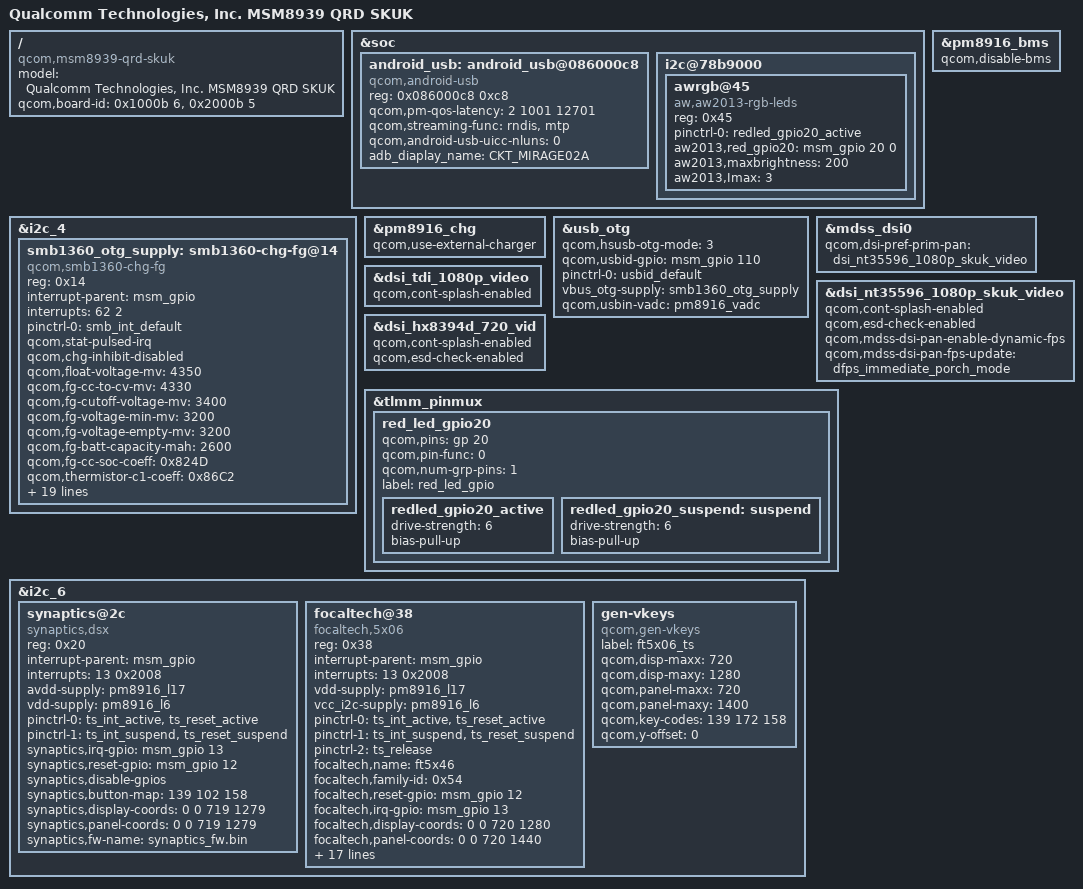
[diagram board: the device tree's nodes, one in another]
/* Copyright (c) 2014, The Linux Foundation. All rights reserved.
 *
 * This program is free software; you can redistribute it and/or modify
 * it under the terms of the GNU General Public License version 2 and
 * only version 2 as published by the Free Software Foundation.
 *
 * This program is distributed in the hope that it will be useful,
 * but WITHOUT ANY WARRANTY; without even the implied warranty of
 * MERCHANTABILITY or FITNESS FOR A PARTICULAR PURPOSE.  See the
 * GNU General Public License for more details.
 */

/dts-v1/;

#include "msm8939.dtsi"
#include "msm8939-qrd-skuk.dtsi"
#include "dsi-panel-nt35596-1080p-skuk-video.dtsi"
#include "dsi-panel-tdi-1080p-video.dtsi"
#include "dsi-panel-hx8394d-720p-video.dtsi"
#include "msm8939-camera-sensor-qrd.dtsi"

/ {
	model = "Qualcomm Technologies, Inc. MSM8939 QRD SKUK";
	compatible = "qcom,msm8939-qrd-skuk", "qcom,msm8939-qrd", "qcom,msm8939", "qcom,qrd";
	qcom,board-id = <0x1000b 6>, <0x2000b 5>;
};

&soc {
	android_usb: android_usb@086000c8 {
		compatible = "qcom,android-usb";
		reg = <0x086000c8 0xc8>;
		qcom,pm-qos-latency = <2 1001 12701>;
		qcom,streaming-func = "rndis","mtp";
		qcom,android-usb-uicc-nluns = /bits/ 8 <0>;
		adb_diaplay_name = "CKT_MIRAGE02A";
	};
};

&i2c_4 {
	smb1360_otg_supply: smb1360-chg-fg@14 {
		compatible = "qcom,smb1360-chg-fg";
		reg = <0x14>;
		interrupt-parent = <&msm_gpio>;
		interrupts = <62 2>;
		pinctrl-names = "default";
		pinctrl-0 = <&smb_int_default>;
		qcom,stat-pulsed-irq;
		qcom,chg-inhibit-disabled;
		/*battery capacity*/
		qcom,float-voltage-mv = <4350>;
		qcom,fg-cc-to-cv-mv = <4330>;
		qcom,fg-cutoff-voltage-mv = <3400>;
		qcom,fg-voltage-min-mv = <3200>;
		qcom,fg-voltage-empty-mv = <3200>;
		qcom,fg-batt-capacity-mah = <2600>;
		qcom,fg-cc-soc-coeff = <0x824D>;
		qcom,thermistor-c1-coeff = <0x86C2>;
		qcom,iterm-ma = <200>;
		qcom,charging-timeout = <1536>;
		qcom,otg-batt-curr-limit = <1500>;
		qcom,recharge-thresh-mv = <100>;
		qcom,thermal-mitigation = <1000 600 300 0>;
	//	qcom,fg-auto-recharge-soc = <99>;
		qcom,empty-soc-disabled;
		regulator-name = "smb1360_otg_vreg";
		/*battery-profile selection properties*/
		qcom,batt-profile-select;
		qcom,smb1360-vadc = <&pm8916_vadc>;
		qcom,batt-id-vref-uv = <1800000>;
		qcom,batt-id-rpullup-kohm = <100>;
		qcom,profile-a-rid-kohm = <33>;
		qcom,profile-b-rid-kohm = <91>;
		qcom,shdn-after-pwroff;
		qcom,config-hard-thresholds;
		qcom,hot-bat-decidegc = <550>;
		qcom,cold-bat-decidegc = <(-150)>;
		qcom,fg-reset-at-pon;
		qcom,hot-bat-mv = <4100>;
	};
};

&pm8916_chg {
	status = "ok";
	qcom,use-external-charger;
};

&pm8916_bms {
	status = "ok";
	qcom,disable-bms;
};
&usb_otg {
	qcom,hsusb-otg-mode = <3>;
	qcom,usbid-gpio = <&msm_gpio 110 0>;
	pinctrl-names = "default";
	pinctrl-0 = <&usbid_default>;
	vbus_otg-supply = <&smb1360_otg_supply>;
	qcom,usbin-vadc = <&pm8916_vadc>;
};
&mdss_dsi0 {
	qcom,dsi-pref-prim-pan = <&dsi_nt35596_1080p_skuk_video>;
};

&dsi_nt35596_1080p_skuk_video {
	qcom,cont-splash-enabled;
	qcom,esd-check-enabled;
	qcom,mdss-dsi-pan-enable-dynamic-fps;
	qcom,mdss-dsi-pan-fps-update = "dfps_immediate_porch_mode";
};


&dsi_tdi_1080p_video {
	qcom,cont-splash-enabled;
};

&dsi_hx8394d_720_vid {
	qcom,cont-splash-enabled;
	qcom,esd-check-enabled;
};

&tlmm_pinmux{
		red_led_gpio20{
			qcom,pins = <&gp 20>;
			qcom,pin-func = <0>;
			qcom,num-grp-pins = <1>;
			label = "red_led_gpio";

			redled_gpio20_active: redled_gpio20_active {
				drive-strength = <6>;
				bias-pull-up;
			};

			redled_gpio20_suspend: suspend {
				drive-strength = <6>;
				bias-pull-up;
			};
		};
};
&soc {
	i2c@78b9000 { /* BLSP1 QUP5 */
		awrgb@45 {
			compatible = "aw,aw2013-rgb-leds";
			reg = <0x45>;
			pinctrl-names = "redled_gpio";
			pinctrl-0 =  <&redled_gpio20_active>;
			aw2013,red_gpio20 = <&msm_gpio 20 0>;
			aw2013,maxbrightness = <200>;
			aw2013,Imax = <3>;
		};
    };
};

&i2c_6 {
	synaptics@2c {
		compatible = "synaptics,dsx";
		reg = <0x20>;
		interrupt-parent = <&msm_gpio>;
		interrupts = <13 0x2008>;
		avdd-supply = <&pm8916_l17>;
		vdd-supply = <&pm8916_l6>;
		pinctrl-names = "pmx_ts_active", "pmx_ts_suspend";
		pinctrl-0 = <&ts_int_active &ts_reset_active>;
		pinctrl-1 = <&ts_int_suspend &ts_reset_suspend>;
		synaptics,irq-gpio = <&msm_gpio 13 0x2008>;
		synaptics,reset-gpio = <&msm_gpio 12 0x0>;
		synaptics,disable-gpios;
		synaptics,button-map = <139 102 158>;
		synaptics,display-coords = <0 0 719 1279>;
		synaptics,panel-coords = <0 0 719 1279>;
		synaptics,fw-name = "synaptics_fw.bin";
	};

	focaltech@38 {
		compatible = "focaltech,5x06";
		reg = <0x38>;
		interrupt-parent = <&msm_gpio>;
		interrupts = <13 0x2008>;
		vdd-supply = <&pm8916_l17>;
		vcc_i2c-supply = <&pm8916_l6>;
		/* pins used by touchscreen */
		pinctrl-names = "pmx_ts_active","pmx_ts_suspend","pmx_ts_release";
		pinctrl-0 = <&ts_int_active &ts_reset_active>;
		pinctrl-1 = <&ts_int_suspend &ts_reset_suspend>;
		pinctrl-2 = <&ts_release>;
		focaltech,name = "ft5x46";
		focaltech,family-id = <0x54>;
		focaltech,reset-gpio = <&msm_gpio 12 0x0>;
		focaltech,irq-gpio = <&msm_gpio 13 0x2008>;
		focaltech,display-coords = <0 0 720 1280>;
		focaltech,panel-coords = <0 0 720 1440>;
		focaltech,button-map= <139 102 158>;
		focaltech,no-force-update;
		focaltech,i2c-pull-up;
		focaltech,group-id = <1>;
		focaltech,hard-reset-delay-ms = <20>;
		focaltech,soft-reset-delay-ms = <200>;
		focaltech,num-max-touches = <5>;
		focaltech,fw-name = "ft_fw.bin";
		focaltech,fw-delay-aa-ms = <30>;
		focaltech,fw-delay-55-ms = <30>;
		focaltech,fw-upgrade-id1 = <0x11>;
		focaltech,fw-upgrade-id2 = <0x11>;
		focaltech,fw-delay-readid-ms = <10>;
		focaltech,fw-delay-era-flsh-ms = <2000>;
		focaltech,fw-auto-cal;
		focaltech,ignore-id-check;
		focaltech,fw-vkey-support;
	};

	gen-vkeys {
		compatible = "qcom,gen-vkeys";
		label = "ft5x06_ts";
		qcom,disp-maxx = <720>;
		qcom,disp-maxy = <1280>;
		qcom,panel-maxx = <720>;
		qcom,panel-maxy = <1400>;
		qcom,key-codes = <139 172 158>;
		qcom,y-offset = <0>;
	};
};


&usb_otg {
       qcom,hsusb-otg-mode = <3>;
       qcom,usbid-gpio = <&msm_gpio 110 0>;
       pinctrl-names = "default";
       pinctrl-0 = <&usbid_default>;
       vbus_otg-supply = <&smb1360_otg_supply>;
};

